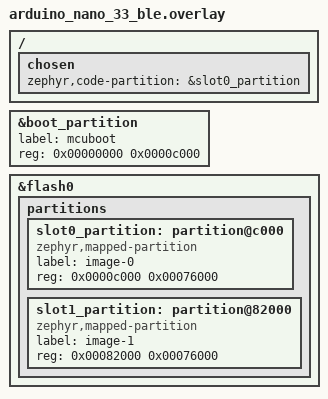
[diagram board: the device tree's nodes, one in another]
/*
 * MCUboot A/B layout for Arduino Nano 33 BLE (Sense) Rev2.
 *
 * Keep this layout synchronized with sysbuild/mcuboot.overlay.
 */

/ {
	chosen {
		zephyr,code-partition = &slot0_partition;
	};
};

&boot_partition {
	label = "mcuboot";
	reg = <0x00000000 0x0000c000>;
	/delete-property/ read-only;
};

/delete-node/ &code_partition;

&flash0 {
	partitions {
		slot0_partition: partition@c000 {
			compatible = "zephyr,mapped-partition";
			label = "image-0";
			reg = <0x0000c000 0x00076000>;
		};

		slot1_partition: partition@82000 {
			compatible = "zephyr,mapped-partition";
			label = "image-1";
			reg = <0x00082000 0x00076000>;
		};
	};
};
